# apollo3p register map
Vendor: Ambiq Micro; Series: Apollo; File version: 1.0
CPU: CM4 r1p0, little endian, MPU, FPU, I-cache, D-cache, VTOR, ITCM, DTCM, 3 interrupt priority bits, 0 interrupts
Registers are 32-bit, read-write, reset 0x0 unless marked. A register's access mark holds for its fields unless they carry their own. Offsets are from the block's base; [hi:lo] are bit positions; {n}, {i} and the like mark numbered series.

## CACHECTRL — FLASH Cache Controller
Base 0x40018000
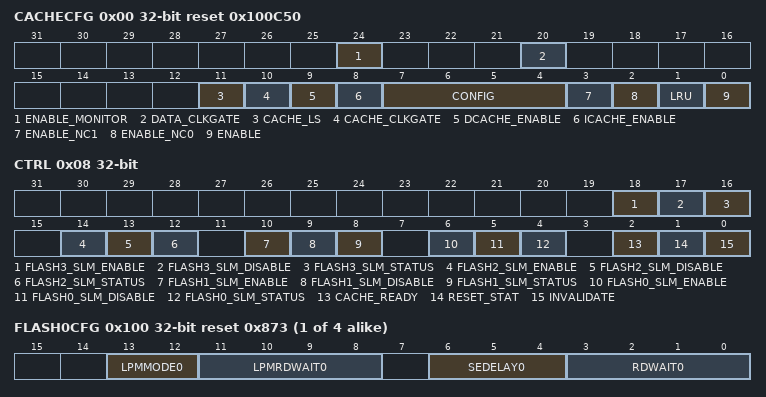
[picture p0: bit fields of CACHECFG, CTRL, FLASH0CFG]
0x00 CACHECFG reset 0x100C50 — FLASH Cache Control
  [24] ENABLE_MONITOR — Enable Cache Monitoring Stats. Cache monitoring consumes additional power and should only be enabled when profiling code and counters will increment when this bit is set. Counter values will be retained when this is set to 0, allowing software to enable/disable counting for multiple code segments.
  [20] DATA_CLKGATE — Enable aggressive clock gating of entire data array. This bit should be set to 1 for optimal power efficiency.
  [11] CACHE_LS — Enable LS (light sleep) of cache RAMs. Software should DISABLE this bit since cache activity is too high to benefit from LS usage.
  [10] CACHE_CLKGATE — Enable clock gating of cache TAG RAM. Software should enable this bit for optimal power efficiency.
  [9] DCACHE_ENABLE — Enable FLASH Data Caching
  [8] ICACHE_ENABLE — Enable FLASH Instruction Caching
  [7:4] CONFIG — Sets the cache configuration
    4=W1_128B_512E (Direct mapped, 128-bit line size, 512 entries (4 SRAMs active)); 5=W2_128B_512E (Two-way set associative, 128-bit line size, 512 entries (8 SRAMs active)); 8=W1_128B_1024E (Direct mapped, 128-bit line size, 1024 entries (8 SRAMs active))
  [3] ENABLE_NC1 — Enable Non-cacheable region 1. See NCR1 registers to define the region.
  [2] ENABLE_NC0 — Enable Non-cacheable region 0. See NCR0 registers to define the region.
  [1] LRU — Sets the cache replacement policy. 0=LRR (least recently replaced), 1=LRU (least recently used). LRR minimizes writes to the TAG SRAM.
  [0] ENABLE — Enables the FLASH cache controller and enables power to the cache SRAMs. The ICACHE_ENABLE and DCACHE_ENABLE should be set to enable caching for each type of access.
0x08 CTRL — Cache Control
  [18] FLASH3_SLM_ENABLE — Enable FLASH Sleep Mode. Write to 1 to put FLASH1 into sleep mode. NOTE: there is a 5 us latency after waking FLASH until the first access will be returned.
  [17] FLASH3_SLM_DISABLE — Disable FLASH Sleep Mode. Write 1 to wake FLASH1 from sleep mode (reading the array will also automatically wake it).
  [16] FLASH3_SLM_STATUS — FLASH Sleep Mode Status. 1 indicates that FLASH1 is in sleep mode, 0 indicates FLASH1 is in normal mode.
  [14] FLASH2_SLM_ENABLE — Enable FLASH Sleep Mode. Write to 1 to put FLASH1 into sleep mode. NOTE: there is a 5 us latency after waking FLASH until the first access will be returned.
  [13] FLASH2_SLM_DISABLE — Disable FLASH Sleep Mode. Write 1 to wake FLASH2 from sleep mode (reading the array will also automatically wake it).
  [12] FLASH2_SLM_STATUS — FLASH Sleep Mode Status. 1 indicates that FLASH2 is in sleep mode, 0 indicates FLASH2 is in normal mode.
  [10] FLASH1_SLM_ENABLE — Enable FLASH Sleep Mode. Write to 1 to put FLASH1 into sleep mode. NOTE: there is a 5 us latency after waking FLASH until the first access will be returned.
  [9] FLASH1_SLM_DISABLE — Disable FLASH Sleep Mode. Write 1 to wake FLASH1 from sleep mode (reading the array will also automatically wake it).
  [8] FLASH1_SLM_STATUS — FLASH Sleep Mode Status. 1 indicates that FLASH1 is in sleep mode, 0 indicates FLASH1 is in normal mode.
  [6] FLASH0_SLM_ENABLE — Enable FLASH Sleep Mode. Write to 1 to put FLASH0 into sleep mode. NOTE: there is a 5 us latency after waking FLASH until the first access will be returned.
  [5] FLASH0_SLM_DISABLE — Disable FLASH Sleep Mode. Write 1 to wake FLASH0 from sleep mode (reading the array will also automatically wake it).
  [4] FLASH0_SLM_STATUS — FLASH Sleep Mode Status. 1 indicates that FLASH0 is in sleep mode, 0 indicates FLASH0 is in normal mode.
  [2] CACHE_READY — Cache Ready Status (enabled and not processing an invalidate operation)
  [1] RESET_STAT — Reset Cache Statistics. When written to a 1, the cache monitor counters will be cleared. The monitor counters can be reset only when the CACHECFG.ENABLE_MONITOR bit is set.
    1=CLEAR (Clear Cache Stats)
  [0] INVALIDATE — Writing a 1 to this bit field invalidates the FLASH cache contents.
0x10 NCR0START — FLASH Cache Noncacheable Region 0 Start
  [26:4] ADDR — Start address for non-cacheable region 0
0x14 NCR0END — FLASH Cache Noncacheable Region 0 End
  [26:4] ADDR — End address for non-cacheable region 0
0x18 NCR1START — FLASH Cache Noncacheable Region 1 Start
  [26:4] ADDR — Start address for non-cacheable region 1
0x1C NCR1END — FLASH Cache Noncacheable Region 1 End
  [26:4] ADDR — End address for non-cacheable region 1
0x40 DMON0 — Data Cache Total Accesses
  [31:0] DACCESS_COUNT — Total accesses to data cache. All performance metrics should be relative to the number of accesses performed.
0x44 DMON1 — Data Cache Tag Lookups
  [31:0] DLOOKUP_COUNT — Total tag lookups from data cache.
0x48 DMON2 — Data Cache Hits
  [31:0] DHIT_COUNT — Cache hits from lookup operations.
0x4C DMON3 — Data Cache Line Hits
  [31:0] DLINE_COUNT — Cache hits from line cache
0x50 IMON0 — Instruction Cache Total Accesses
  [31:0] IACCESS_COUNT — Total accesses to Instruction cache
0x54 IMON1 — Instruction Cache Tag Lookups
  [31:0] ILOOKUP_COUNT — Total tag lookups from Instruction cache
0x58 IMON2 — Instruction Cache Hits
  [31:0] IHIT_COUNT — Cache hits from lookup operations
0x5C IMON3 — Instruction Cache Line Hits
  [31:0] ILINE_COUNT — Cache hits from line cache
{0x100+4i} FLASH{i}CFG reset 0x873 (i=0..3) — FLASH {i} Control
  [13:12] LPMMODE{i} — Controls FLASH low power modes (control of LPM pin).
    0=NEVER (High power mode (LPM not used).); 1=STANDBY (Fast Standby mode. LPM deasserted for read operations, but asserted while FLASH IDLE.); 2=ALWAYS (Low Power mode. LPM always asserted for reads. LPM_RD_WAIT must be programmed to accommodate longer read access times.)
  [11:8] LPMRDWAIT{i} — Sets FLASH wait states when in LPM Mode 2 (RD_WAIT in LPM mode 2 only)
  [6:4] SEDELAY{i} — Sets SE delay (FLASH address setup). A value of 5 is recommended.
  [3:0] RDWAIT{i} — Sets read wait states for normal (fast) operation. A value of 1 is recommended.
